# nrf9230_sysctrl register map
Vendor: Nordic Semiconductor; Series: nRF92; File version: 1
Registers are 32-bit, read-write, reset 0x0 unless marked. A register's access mark holds for its fields unless they carry their own. Offsets are from the block's base; [hi:lo] are bit positions; lines under a group give offsets from that group; {n}, {i} and the like mark numbered series; 'fields as' and 'values as' point back to an identical list.

## OSCRFR — OSCRFR peripheral
Base 0x5F96B000
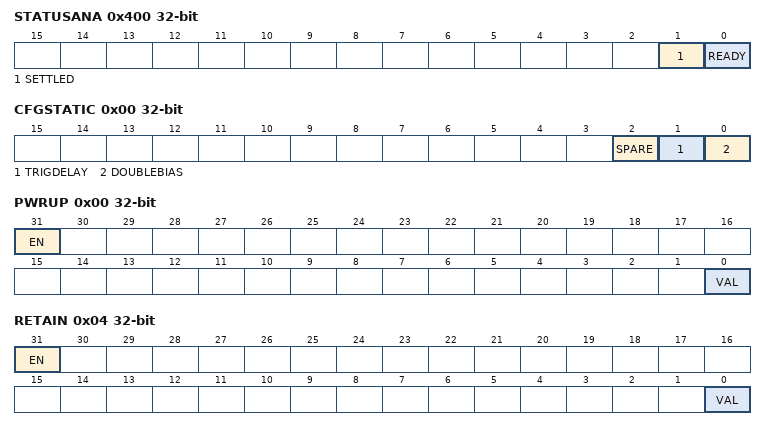
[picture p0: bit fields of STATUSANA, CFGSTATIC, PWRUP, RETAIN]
0x400 STATUSANA ro — Status of analog module output signals
  [1] SETTLED — Current value of the SETTLED signal from the analog module
  [0] READY — Current value of the READY signal from the analog module
0x410 CONFIG group — Unspecified
  0x00 CFGSTATIC — OSCRFR static CFG configuration
    [2] SPARE
    [1] TRIGDELAY — Increase TRIG signal delay
      0=Disabled; 1=Enabled
    [0] DOUBLEBIAS — Enable double bias
      0=Disabled; 1=Enabled
0x440 TRIM group — Unspecified
  0x00 OSC — Oscillation period trimming
    [2:0] VAL — Oscillation period trimming value
      0=Normal trim value; 1=Oscillation period increases by 35 percent; 2=Oscillation period increases by 154 percent; 3=Oscillation period increases by 670 percent; 4=ValNeg54 (Oscillation period decreases by 54 percent); 5=ValNeg49 (Oscillation period decreases by 49 percent); 6=ValNeg37 (Oscillation period decreases by 37 percent); 7=ValNeg26 (Oscillation period decreases by 26 percent)
  0x04 IBPSR — IBPSR current trimming
    [3:0] VAL — IBPSR current and VREF voltage trimming value
0x480 MIRROR reset 0x1 — Enable LOCK for mirrored registers
  [0] LOCK — Lock for mirrored registers
    0=Disabled (Lock disabled); 1=Enabled (Lock enabled)
0x484 MODE — Oscillator mode
  [0] MODE
    0=Normal mode - Use internal oscillator; 1=Bypass mode - Use OSC_RFR_DIG_AO_0V8 signal
0x500 OVERRIDE group — Unspecified
  0x00 PWRUP — Override the PWRUP signal to the analog module
    [31] EN — Enable the override
      0=Disabled (Override is disabled); 1=Enabled (Override is enabled)
    [0] VAL — Override value for the signal
  0x04 RETAIN — Override the RETAIN signal to the analog module
    fields as OVERRIDE.PWRUP
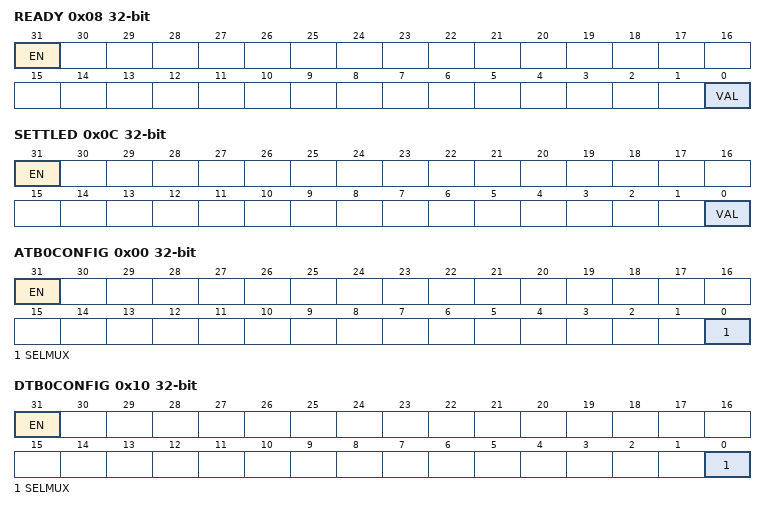
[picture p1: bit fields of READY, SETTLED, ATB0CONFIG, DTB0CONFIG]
  0x08 READY — Override the READY signal from the analog module
    [31] EN — Enable the override
      values as OVERRIDE.PWRUP.EN
    [0] VAL — Current value of the signal
  0x0C SETTLED — Override the SETTLED signal from the analog module
    fields as OVERRIDE.READY
0x600 DFT group — Unspecified
  0x00 ATB0CONFIG — Analog Test Bus 0 (ATB0) configuration
    [31] EN — Enable the analog test bus
      0=Disabled (Analog test bus is disabled); 1=Enabled (Analog test bus is enabled)
    [0] SELMUX — Select multiplexer for ATB0
      0=IBPSR4U (IBPSR_4U signal selected); 1=Spare (None selected)
  0x10 DTB0CONFIG — Digital Test Bus 0 (DTB0) configuration
    [31] EN — Enable the digital test bus
      0=Disabled (Digital test bus is disabled); 1=Enabled (Digital test bus is enabled)
    [0] SELMUX — Select multiplexer for DTB0
      0=READY (READY signal selected); 1=OSC (OSC_RFR_ANA_AO_0V8 signal selected)
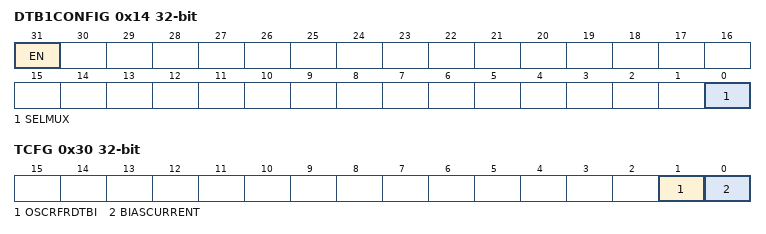
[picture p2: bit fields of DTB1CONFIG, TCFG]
  0x14 DTB1CONFIG — Digital Test Bus 1 (DTB1) configuration
    [31] EN — Enable the digital test bus
      values as DFT.DTB0CONFIG.EN
    [0] SELMUX — Select multiplexer for DTB1
      0=SETTLED (SETTLED signal selected); 1=OSC (OSC_RFR_ANA_AO_0V8 signal selected)
  0x1C DTB3CONFIG — Digital Test Bus 3 (DTB3) configuration
    [27] PWRUPDELTEST — Enable the PWRUP delay test circuit
      0=Disabled (PWRUP delay test circuit is disabled); 1=Enabled (PWRUP delay test circuit is enabled)
  0x30 TCFG — Test mode configuration
    [1] OSCRFRDTBI — Use DTBI input as refresh clock when in bypass mode
      0=Disabled; 1=Enabled
    [0] BIASCURRENT — Enable continuous mode for measuring bias current over ATB
      0=Disabled; 1=Enabled

## VDETIO — VDETIO peripheral
Base 0x5F974000
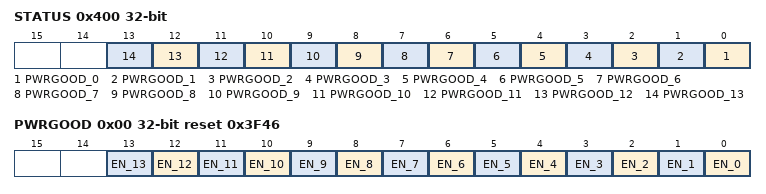
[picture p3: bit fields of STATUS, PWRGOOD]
0x400 STATUS ro — Voltage detector status
  [all] fields
    0=AboveThr (Power good detector detected voltage above threshold level); 1=BelowThr (Power good detector detected voltage below threshold level)
  [n] PWRGOOD_{n} (n=0..13) — Power good detector status for port [{n}]
0x410 CONFIG group — Unspecified
  0x00 PWRGOOD reset 0x3F46 — Power good detector configuration
    [all] fields
      0=Disabled (IO voltage detector is disabled); 1=Enabled (IO voltage detector is enabled)
    [n] EN_{n} (n=0..13) — Enable the power good detector for port [{n}]

## VSPOWERC — VSPOWERC peripheral
Base 0x5F977000
{0x410+8i} CONFIG[{i}] (i=0..1) group — Unspecified
  0x00 PWRSRC — Description cluster: Power source select for dual power switch domain [n]
    [0] SRC — Selecting between VS and AO power
      0=SelVS (Voltage scaled VDD_VS_0V8); 1=SelAO (Always-on VDD_AO_0V8)
  0x04 OVERLAP — Description cluster: Configuration of switch control overlap time for dual power switch domain [n]
    [3:0] VAL — Overlap time, both power requests active
{0x500+4i} OVERRIDE[{i}] (i=0..1) group — Unspecified
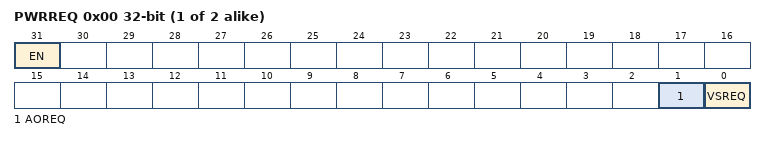
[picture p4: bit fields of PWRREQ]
  0x00 PWRREQ — Description cluster: Override the power requests for dual power switch domain [n]
    [31] EN — Enable the override
      0=Disabled (Override is disabled); 1=Enabled (Override is enabled)
    [1] AOREQ — Override value for the VDD_AO_0V8 power request
    [0] VSREQ — Override value for the VDD_VS_0V8 power request

## Notices in the file
Copyright (c) 2010 - 2024, Nordic Semiconductor ASA
All rights reserved.
Redistribution and use in source and binary forms, with or without modification,
are permitted provided that the following conditions are met:
1. Redistributions of source code must retain the above copyright notice, this
list of conditions and the following disclaimer.
2. Redistributions in binary form, except as embedded into a Nordic
Semiconductor ASA integrated circuit in a product or a software update for
such product, must reproduce the above copyright notice, this list of
conditions and the following disclaimer in the documentation and/or other
materials provided with the distribution.
3. Neither the name of Nordic Semiconductor ASA nor the names of its
contributors may be used to endorse or promote products derived from this
software without specific prior written permission.
4. This software, with or without modification, must only be used with a
Nordic Semiconductor ASA integrated circuit.
5. Any software provided in binary form under this license must not be reverse
engineered, decompiled, modified and/or disassembled.
THIS SOFTWARE IS PROVIDED BY NORDIC SEMICONDUCTOR ASA "AS IS" AND ANY EXPRESS
OR IMPLIED WARRANTIES, INCLUDING, BUT NOT LIMITED TO, THE IMPLIED WARRANTIES
OF MERCHANTABILITY, NONINFRINGEMENT, AND FITNESS FOR A PARTICULAR PURPOSE ARE
DISCLAIMED. IN NO EVENT SHALL NORDIC SEMICONDUCTOR ASA OR CONTRIBUTORS BE
LIABLE FOR ANY DIRECT, INDIRECT, INCIDENTAL, SPECIAL, EXEMPLARY, OR
CONSEQUENTIAL DAMAGES (INCLUDING, BUT NOT LIMITED TO, PROCUREMENT OF SUBSTITUTE
GOODS OR SERVICES; LOSS OF USE, DATA, OR PROFITS; OR BUSINESS INTERRUPTION)
HOWEVER CAUSED AND ON ANY THEORY OF LIABILITY, WHETHER IN CONTRACT, STRICT
LIABILITY, OR TORT (INCLUDING NEGLIGENCE OR OTHERWISE) ARISING IN ANY WAY OUT
OF THE USE OF THIS SOFTWARE, EVEN IF ADVISED OF THE POSSIBILITY OF SUCH DAMAGE.
